# AS32x601 register map
File version: 1.0
CPU: RISC-V, little endian
Registers are 32-bit, read-write, reset 0x0 unless marked. A register's access mark holds for its fields unless they carry their own. Offsets are from the block's base; [hi:lo] are bit positions.

## SPACC — Security Packet Acceleration Controller
Base 0x41100000
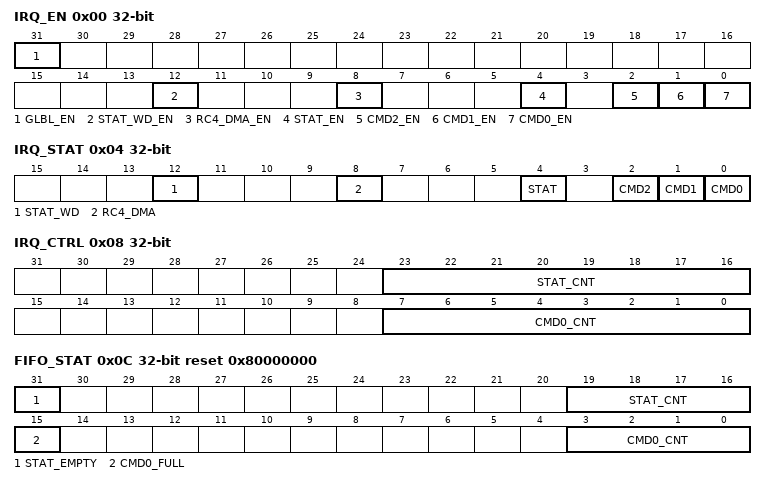
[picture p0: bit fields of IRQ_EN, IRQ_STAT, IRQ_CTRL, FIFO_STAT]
0x00 IRQ_EN — SPACC Interrupt Enable Register
  [31] GLBL_EN — SPACC Global Enable Control For Interrupt Sources
  [12] STAT_WD_EN — SPACC Status Watchdog Interrupt Enable
  [8] RC4_DMA_EN — RC4 DMA Interrupt Enable
  [4] STAT_EN — SPACC Status FIFO Interrupt Enable
  [2] CMD2_EN — SPACC Command FIFO Priority 2 Interrupt Enable
  [1] CMD1_EN — SPACC Command FIFO Priority 1 Interrupt Enable
  [0] CMD0_EN — SPACC Command FIFO Priority 0 Interrupt Enable
0x04 IRQ_STAT — SPACC Interrupt Status Register
  [12] STAT_WD — SPACC Status Watchdog Interrupt Status
  [8] RC4_DMA — RC4 DMA Interrupt Status
  [4] STAT — SPACC Status FIFO Interrupt Status
  [2] CMD2 — SPACC Command FIFO Priority 2 Interrupt Status
  [1] CMD1 — SPACC Command FIFO Priority 1 Interrupt Status
  [0] CMD0 — SPACC Command FIFO Priority 0 Interrupt Status
0x08 IRQ_CTRL — SPACC Interrupt Control Register
  [23:16] STAT_CNT — SPACC FIFO Fill Level To Trigger A STAT Interrupt
  [7:0] CMD0_CNT — SPACC FIFO Fill Level To Trigger A CMD0 Interrupt
0x0C FIFO_STAT ro reset 0x80000000 — SPACC FIFO Status Register
  [31] STAT_EMPTY — Flag Indicating That The STAT FIFO Is Empty
  [19:16] STAT_CNT — SPACC Current Number Of Status Values Enqueued In The STAT FIFO
  [15] CMD0_FULL — Flag Indicating That The CMD0 FIFO Is Full
  [3:0] CMD0_CNT — SPACC Current Number Of Commands Enqueued In The CMD0 FIFO
0x20 SRC_PTR — SPACC Source Pointer Register
  [31:3] PTR — SPACC Pointer To Source Packet Data Structure In System Memory
0x24 DST_PTR — SPACC Destination Pointer Register
  [31:3] PTR — SPACC Pointer To Destination Packet Data Structure In System Memory
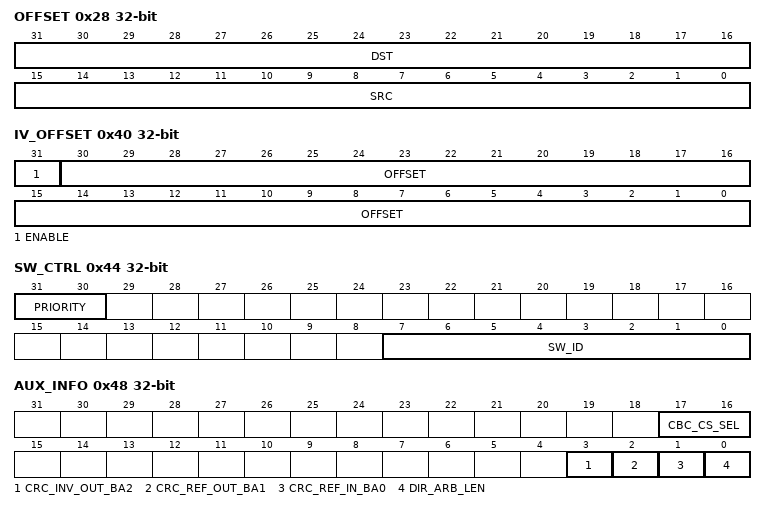
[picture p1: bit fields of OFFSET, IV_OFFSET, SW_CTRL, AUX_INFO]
0x28 OFFSET — SPACC Offset Register
  [31:16] DST — SPACC Destination Buffer Offset
  [15:0] SRC — SPACC Source Buffer Offset
0x2C PRE_AAD_LEN — SPACC Prefixed AAD Length Register
  [31:0] LEN — SPACC Byte Length Of The Prefixed AAD
0x30 POST_AAD_LEN — SPACC Postfixed AAD Length Register
  [31:0] LEN — SPACC Byte Length Of The Postfix AAD
0x34 PROC_LEN — SPACC Packet Length Register
  [31:0] LEN — SPACC Byte Length Of The Data To Be Processed
0x38 ICV_LEN — SPACC ICV Length Register
  [31:0] LEN — SPACC Byte Length Of The ICV
0x3C ICV_OFFSET — SPACC ICV Offset Register
  [31:0] OFFSET — SPACC Byte Offset Of The ICV
0x40 IV_OFFSET — SPACC IV Offset Register
  [31] ENABLE — IV Offset Enable
  [30:0] OFFSET — SPACC Byte Offset Of The IV
0x44 SW_CTRL — SPACC Software Control Register
  [31:30] PRIORITY — Selects The Prioritized Command FIFO To Be Used For Command Dispatch
  [7:0] SW_ID — Software Tag Of Job ID
0x48 AUX_INFO — SPACC Auxiliary Information Register
  [17:16] CBC_CS_SEL — Selects the CTS mode to apply for SM4-CBC
  [3] CRC_INV_OUT_BA2 — For the CRC-32 operation, invert all the bits of the output
  [2] CRC_REF_OUT_BA1 — For the CRC-32 operation, perform bit reflection on the 32-bit output result
  [1] CRC_REF_IN_BA0 — For CRC-32 operations, this bit is used to perform bit reflection on the input
  [0] DIR_ARB_LEN — For KASUMI-f9, this field is used to set the direction bit (uplink/downlink)
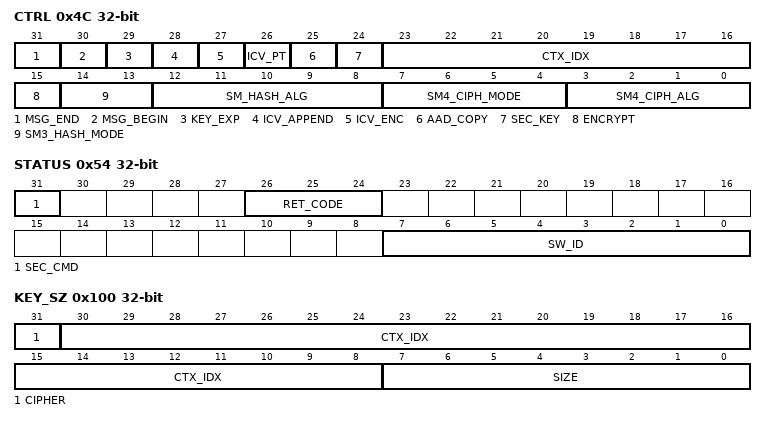
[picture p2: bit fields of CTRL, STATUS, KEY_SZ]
0x4C CTRL — SPACC Control Register
  [31] MSG_END — End Flag For Partial Packet Processing
  [30] MSG_BEGIN — Begin Flag For Partial Packet Processing
  [29] KEY_EXP — Key Expansion
  [28] ICV_APPEND — ICV Computed Appended
  [27] ICV_ENC — ICV Computed Encrypted
  [26] ICV_PT — ICV Computed Set
  [25] AAD_COPY — Copy The PRE_AAD To The Destination Buffer
  [24] SEC_KEY — Use The Secure Key Port For Fetching Cipher Key Information
  [23:16] CTX_IDX — Context Index
  [15] ENCRYPT — Transform To Apply
  [14:13] SM3_HASH_MODE — SM3 Hash Mode To Use
  [12:8] SM_HASH_ALG — Hash Algorithm To Employ
  [7:4] SM4_CIPH_MODE — SM4 Cipher Mode To Use
  [3:0] SM4_CIPH_ALG — Cipher Algorithm To Employ
0x50 STAT_POP wo — SPACC Status FIFO POP Register
  [0] POP — SPACC Status FIFO Pop
0x54 STATUS ro — SPACC Status FIFO Register
  [31] SEC_CMD — Indicates If The Command Executed In Secure Or Normal Mode
  [26:24] RET_CODE — Result Of Operation
  [7:0] SW_ID — Software Tag Of Job ID
0x80 STAT_WD_CTRL reset 0x262144 — SPACC Status Watchdog Register
  [23:0] TIMER — SPACC Status Watchdog Timer
0x100 KEY_SZ — SPACC Key Size Register
  [31] CIPHER — Indicates Whether This Key Size Is A Cipher Key Or A Hash Key
  [30:8] CTX_IDX — Context Index
  [7:0] SIZE — Key Size
